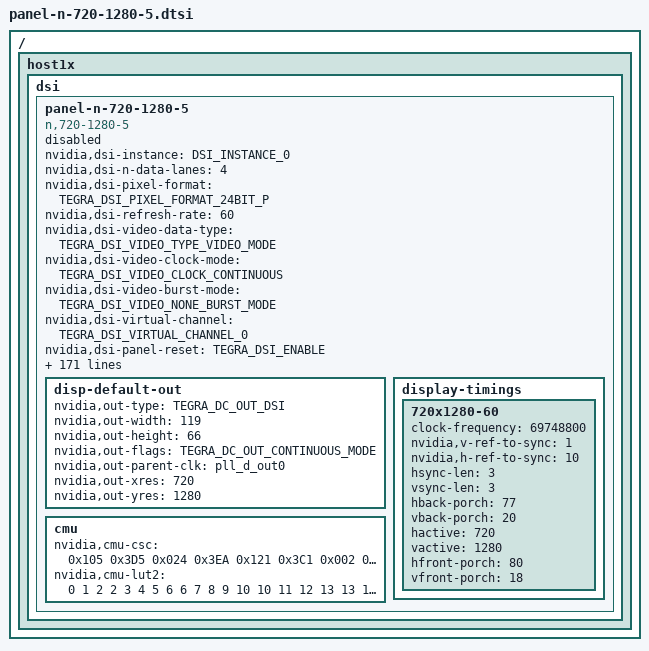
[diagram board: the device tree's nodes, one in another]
/*
 * arch/arm/boot/dts/panel-n-720-1280-5.dtsi
 *
 * Copyright (c) 2014, NVIDIA CORPORATION.  All rights reserved.
 *
 * This program is free software; you can redistribute it and/or modify
 * it under the terms of the GNU General Public License as published by
 * the Free Software Foundation; either version 2 of the License, or
 * (at your option) any later version.
 *
 * This program is distributed in the hope that it will be useful, but WITHOUT
 * ANY WARRANTY; without even the implied warranty of MERCHANTABILITY or
 * FITNESS FOR A PARTICULAR PURPOSE.  See the GNU General Public License for
 * more details.
 *
 * You should have received a copy of the GNU General Public License along
 * with this program; if not, write to the Free Software Foundation, Inc.,
 * 51 Franklin Street, Fifth Floor, Boston, MA  02110-1301, USA.
 */
#include <dt-bindings/display/tegra-dc.h>
#include <dt-bindings/display/tegra-panel.h>

/ {
	host1x {
		dsi {
			panel-n-720-1280-5 {
				status = "disabled";
				compatible = "n,720-1280-5", "none,panel-generic";

				nvidia,dsi-instance = <DSI_INSTANCE_0>;
				nvidia,dsi-n-data-lanes = <4>;
				nvidia,dsi-pixel-format = <TEGRA_DSI_PIXEL_FORMAT_24BIT_P>;
				nvidia,dsi-refresh-rate = <60>;
				nvidia,dsi-video-data-type = <TEGRA_DSI_VIDEO_TYPE_VIDEO_MODE>;
				nvidia,dsi-video-clock-mode = <TEGRA_DSI_VIDEO_CLOCK_CONTINUOUS>;
				nvidia,dsi-video-burst-mode = <TEGRA_DSI_VIDEO_NONE_BURST_MODE>;
				nvidia,dsi-virtual-channel = <TEGRA_DSI_VIRTUAL_CHANNEL_0>;
				nvidia,dsi-panel-reset = <TEGRA_DSI_ENABLE>;
				nvidia,dsi-power-saving-suspend = <TEGRA_DSI_ENABLE>;

				/* Long Packet: <PACKETTYPE[u8] COMMANDID[u8] PAYLOADCOUNT[u16] ECC[u8] PAYLOAD[..] CHECKSUM[u16]> */
				/* Short Packet: <PACKETTYPE[u8] COMMANDID[u8] DATA0[u8] DATA1[u8] ECC[u8]> */
				/* For DSI packets each DT cell is interpreted as u8 not u32 */
				nvidia,dsi-init-cmd =
					<TEGRA_DSI_DELAY_MS 130>,
					<TEGRA_DSI_PACKET_CMD DSI_GENERIC_LONG_WRITE 0x06 0x00 0x00 0xF0 0x55 0xAA 0x52 0x08 0x00 0x00 0x00>,
					<TEGRA_DSI_PACKET_CMD DSI_GENERIC_LONG_WRITE 0x05 0x00 0x00 0xFF 0xAA 0x55 0xA5 0x80 0x00 0x00>,
					<TEGRA_DSI_PACKET_CMD DSI_GENERIC_LONG_WRITE 0x02 0x00 0x00 0x6F 0x13 0x00 0x00>,
					<TEGRA_DSI_PACKET_CMD DSI_GENERIC_LONG_WRITE 0x02 0x00 0x00 0xF7 0x00 0x00 0x00>,
					<TEGRA_DSI_PACKET_CMD DSI_GENERIC_LONG_WRITE 0x02 0x00 0x00 0x6F 0x01 0x00 0x00>, /* ccmon */
					<TEGRA_DSI_PACKET_CMD DSI_GENERIC_LONG_WRITE 0x02 0x00 0x00 0xB1 0x21 0x00 0x00>,
					<TEGRA_DSI_PACKET_CMD DSI_GENERIC_LONG_WRITE 0x02 0x00 0x00 0x6F 0x02 0x00 0x00>,
					<TEGRA_DSI_PACKET_CMD DSI_GENERIC_LONG_WRITE 0x02 0x00 0x00 0xB8 0x0C 0x00 0x00>,
					<TEGRA_DSI_PACKET_CMD DSI_GENERIC_LONG_WRITE 0x03 0x00 0x00 0xBB 0x11 0x11 0x00 0x00>,
					<TEGRA_DSI_PACKET_CMD DSI_GENERIC_LONG_WRITE 0x03 0x00 0x00 0xBC 0x00 0x00 0x00 0x00>,
					<TEGRA_DSI_PACKET_CMD DSI_GENERIC_LONG_WRITE 0x02 0x00 0x00 0xB6 0x0F 0x00 0x00>, /* Modify by HSD */
					<TEGRA_DSI_PACKET_CMD DSI_GENERIC_LONG_WRITE 0x02 0x00 0x00 0xC8 0x80 0x00 0x00>,
					<TEGRA_DSI_PACKET_CMD DSI_GENERIC_LONG_WRITE 0x06 0x00 0x00 0xF0 0x55 0xAA 0x52 0x08 0x01 0x00 0x00>,
					<TEGRA_DSI_PACKET_CMD DSI_GENERIC_LONG_WRITE 0x03 0x00 0x00 0xB0 0x09 0x09 0x00 0x00>,
					<TEGRA_DSI_PACKET_CMD DSI_GENERIC_LONG_WRITE 0x03 0x00 0x00 0xB1 0x09 0x09 0x00 0x00>,
					<TEGRA_DSI_PACKET_CMD DSI_GENERIC_LONG_WRITE 0x03 0x00 0x00 0xBC 0xA0 0x00 0x00 0x00>,
					<TEGRA_DSI_PACKET_CMD DSI_GENERIC_LONG_WRITE 0x03 0x00 0x00 0xBD 0xA0 0x00 0x00 0x00>,
					<TEGRA_DSI_PACKET_CMD DSI_GENERIC_LONG_WRITE 0x02 0x00 0x00 0xCA 0x00 0x00 0x00>,
					<TEGRA_DSI_PACKET_CMD DSI_GENERIC_LONG_WRITE 0x02 0x00 0x00 0xC0 0x04 0x00 0x00>,
					<TEGRA_DSI_PACKET_CMD DSI_GENERIC_LONG_WRITE 0x03 0x00 0x00 0xB5 0x03 0x03 0x00 0x00>,
					<TEGRA_DSI_PACKET_CMD DSI_GENERIC_LONG_WRITE 0x02 0x00 0x00 0xBE 0x60 0x00 0x00>,
					<TEGRA_DSI_PACKET_CMD DSI_GENERIC_LONG_WRITE 0x03 0x00 0x00 0xB3 0x28 0x28 0x00 0x00>,
					<TEGRA_DSI_PACKET_CMD DSI_GENERIC_LONG_WRITE 0x03 0x00 0x00 0xB4 0x0F 0x0F 0x00 0x00>,
					<TEGRA_DSI_PACKET_CMD DSI_GENERIC_LONG_WRITE 0x03 0x00 0x00 0xB9 0x35 0x35 0x00 0x00>,
					<TEGRA_DSI_PACKET_CMD DSI_GENERIC_LONG_WRITE 0x03 0x00 0x00 0xBA 0x14 0x14 0x00 0x00>,
					<TEGRA_DSI_PACKET_CMD DSI_GENERIC_LONG_WRITE 0x06 0x00 0x00 0xF0 0x55 0xAA 0x52 0x08 0x02 0x00 0x00>,
					<TEGRA_DSI_PACKET_CMD DSI_GENERIC_LONG_WRITE 0x02 0x00 0x00 0xEE 0x01 0x00 0x00>,
					<TEGRA_DSI_PACKET_CMD DSI_GENERIC_LONG_WRITE 0x11 0x00 0x00 0xB0 0x00 0x00 0x00 0x17 0x00 0x3C 0x00 0x58 0x00 0x6D 0x00 0x92 0x00 0xAA 0x00 0xE2 0x00 0x00>, /* New GMA code */
					<TEGRA_DSI_PACKET_CMD DSI_GENERIC_LONG_WRITE 0x11 0x00 0x00 0xB1 0x01 0x08 0x01 0x44 0x01 0x73 0x01 0xBD 0x01 0xFA 0x01 0xFD 0x02 0x38 0x02 0x74 0x00 0x00>,
					<TEGRA_DSI_PACKET_CMD DSI_GENERIC_LONG_WRITE 0x11 0x00 0x00 0xB2 0x02 0x9B 0x02 0xCB 0x02 0xEC 0x03 0x17 0x03 0x2F 0x03 0x4E 0x03 0x81 0x03 0xD6 0x00 0x00>,
					<TEGRA_DSI_PACKET_CMD DSI_GENERIC_LONG_WRITE 0x05 0x00 0x00 0xB3 0x03 0xFB 0x03 0xFF 0x00 0x00>,
					<TEGRA_DSI_PACKET_CMD DSI_GENERIC_LONG_WRITE 0x06 0x00 0x00 0xF0 0x55 0xAA 0x52 0x08 0x06 0x00 0x00>,
					<TEGRA_DSI_PACKET_CMD DSI_GENERIC_LONG_WRITE 0x03 0x00 0x00 0xB0 0x2D 0x2E 0x00 0x00>,
					<TEGRA_DSI_PACKET_CMD DSI_GENERIC_LONG_WRITE 0x03 0x00 0x00 0xB1 0x29 0x2A 0x00 0x00>,
					<TEGRA_DSI_PACKET_CMD DSI_GENERIC_LONG_WRITE 0x03 0x00 0x00 0xB2 0x16 0x18 0x00 0x00>,
					<TEGRA_DSI_PACKET_CMD DSI_GENERIC_LONG_WRITE 0x03 0x00 0x00 0xB3 0x10 0x12 0x00 0x00>,
					<TEGRA_DSI_PACKET_CMD DSI_GENERIC_LONG_WRITE 0x03 0x00 0x00 0xB4 0x00 0x02 0x00 0x00>,
					<TEGRA_DSI_PACKET_CMD DSI_GENERIC_LONG_WRITE 0x03 0x00 0x00 0xB5 0x31 0x31 0x00 0x00>,
					<TEGRA_DSI_PACKET_CMD DSI_GENERIC_LONG_WRITE 0x03 0x00 0x00 0xB6 0x31 0x31 0x00 0x00>,
					<TEGRA_DSI_PACKET_CMD DSI_GENERIC_LONG_WRITE 0x03 0x00 0x00 0xB7 0x31 0x31 0x00 0x00>,
					<TEGRA_DSI_PACKET_CMD DSI_GENERIC_LONG_WRITE 0x03 0x00 0x00 0xB8 0x31 0x31 0x00 0x00>,
					<TEGRA_DSI_PACKET_CMD DSI_GENERIC_LONG_WRITE 0x03 0x00 0x00 0xB9 0x31 0x31 0x00 0x00>,
					<TEGRA_DSI_PACKET_CMD DSI_GENERIC_LONG_WRITE 0x03 0x00 0x00 0xBA 0x31 0x31 0x00 0x00>,
					<TEGRA_DSI_PACKET_CMD DSI_GENERIC_LONG_WRITE 0x03 0x00 0x00 0xBB 0x31 0x31 0x00 0x00>,
					<TEGRA_DSI_PACKET_CMD DSI_GENERIC_LONG_WRITE 0x03 0x00 0x00 0xBC 0x31 0x31 0x00 0x00>,
					<TEGRA_DSI_PACKET_CMD DSI_GENERIC_LONG_WRITE 0x03 0x00 0x00 0xBD 0x31 0x31 0x00 0x00>,
					<TEGRA_DSI_PACKET_CMD DSI_GENERIC_LONG_WRITE 0x03 0x00 0x00 0xBE 0x31 0x31 0x00 0x00>,
					<TEGRA_DSI_PACKET_CMD DSI_GENERIC_LONG_WRITE 0x03 0x00 0x00 0xBF 0x03 0x01 0x00 0x00>,
					<TEGRA_DSI_PACKET_CMD DSI_GENERIC_LONG_WRITE 0x03 0x00 0x00 0xC0 0x13 0x11 0x00 0x00>,
					<TEGRA_DSI_PACKET_CMD DSI_GENERIC_LONG_WRITE 0x03 0x00 0x00 0xC1 0x19 0x17 0x00 0x00>,
					<TEGRA_DSI_PACKET_CMD DSI_GENERIC_LONG_WRITE 0x03 0x00 0x00 0xC2 0x2A 0x29 0x00 0x00>,
					<TEGRA_DSI_PACKET_CMD DSI_GENERIC_LONG_WRITE 0x03 0x00 0x00 0xC3 0x2E 0x2D 0x00 0x00>,
					<TEGRA_DSI_PACKET_CMD DSI_GENERIC_LONG_WRITE 0x03 0x00 0x00 0xE5 0x31 0x31 0x00 0x00>,
					<TEGRA_DSI_PACKET_CMD DSI_GENERIC_LONG_WRITE 0x03 0x00 0x00 0xC4 0x2E 0x2D 0x00 0x00>,
					<TEGRA_DSI_PACKET_CMD DSI_GENERIC_LONG_WRITE 0x03 0x00 0x00 0xC5 0x29 0x2A 0x00 0x00>,
					<TEGRA_DSI_PACKET_CMD DSI_GENERIC_LONG_WRITE 0x03 0x00 0x00 0xC6 0x13 0x11 0x00 0x00>,
					<TEGRA_DSI_PACKET_CMD DSI_GENERIC_LONG_WRITE 0x03 0x00 0x00 0xC7 0x19 0x17 0x00 0x00>,
					<TEGRA_DSI_PACKET_CMD DSI_GENERIC_LONG_WRITE 0x03 0x00 0x00 0xC8 0x03 0x01 0x00 0x00>,
					<TEGRA_DSI_PACKET_CMD DSI_GENERIC_LONG_WRITE 0x03 0x00 0x00 0xC9 0x31 0x31 0x00 0x00>,
					<TEGRA_DSI_PACKET_CMD DSI_GENERIC_LONG_WRITE 0x03 0x00 0x00 0xCA 0x31 0x31 0x00 0x00>,
					<TEGRA_DSI_PACKET_CMD DSI_GENERIC_LONG_WRITE 0x03 0x00 0x00 0xCB 0x31 0x31 0x00 0x00>,
					<TEGRA_DSI_PACKET_CMD DSI_GENERIC_LONG_WRITE 0x03 0x00 0x00 0xCC 0x31 0x31 0x00 0x00>,
					<TEGRA_DSI_PACKET_CMD DSI_GENERIC_LONG_WRITE 0x03 0x00 0x00 0xCD 0x31 0x31 0x00 0x00>,
					<TEGRA_DSI_PACKET_CMD DSI_GENERIC_LONG_WRITE 0x03 0x00 0x00 0xCE 0x31 0x31 0x00 0x00>,
					<TEGRA_DSI_PACKET_CMD DSI_GENERIC_LONG_WRITE 0x03 0x00 0x00 0xCF 0x31 0x31 0x00 0x00>,
					<TEGRA_DSI_PACKET_CMD DSI_GENERIC_LONG_WRITE 0x03 0x00 0x00 0xD0 0x31 0x31 0x00 0x00>,
					<TEGRA_DSI_PACKET_CMD DSI_GENERIC_LONG_WRITE 0x03 0x00 0x00 0xD1 0x31 0x31 0x00 0x00>,
					<TEGRA_DSI_PACKET_CMD DSI_GENERIC_LONG_WRITE 0x03 0x00 0x00 0xD2 0x31 0x31 0x00 0x00>,
					<TEGRA_DSI_PACKET_CMD DSI_GENERIC_LONG_WRITE 0x03 0x00 0x00 0xD3 0x00 0x02 0x00 0x00>,
					<TEGRA_DSI_PACKET_CMD DSI_GENERIC_LONG_WRITE 0x03 0x00 0x00 0xD4 0x16 0x18 0x00 0x00>,
					<TEGRA_DSI_PACKET_CMD DSI_GENERIC_LONG_WRITE 0x03 0x00 0x00 0xD5 0x10 0x12 0x00 0x00>,
					<TEGRA_DSI_PACKET_CMD DSI_GENERIC_LONG_WRITE 0x03 0x00 0x00 0xD6 0x2A 0x29 0x00 0x00>,
					<TEGRA_DSI_PACKET_CMD DSI_GENERIC_LONG_WRITE 0x03 0x00 0x00 0xD7 0x2D 0x2E 0x00 0x00>,
					<TEGRA_DSI_PACKET_CMD DSI_GENERIC_LONG_WRITE 0x03 0x00 0x00 0xE6 0x31 0x31 0x00 0x00>,
					<TEGRA_DSI_PACKET_CMD DSI_GENERIC_LONG_WRITE 0x06 0x00 0x00 0xD8 0x00 0x00 0x00 0x00 0x00 0x00 0x00>,
					<TEGRA_DSI_PACKET_CMD DSI_GENERIC_LONG_WRITE 0x06 0x00 0x00 0xD9 0x00 0x00 0x00 0x00 0x00 0x00 0x00>,
					<TEGRA_DSI_PACKET_CMD DSI_GENERIC_LONG_WRITE 0x02 0x00 0x00 0xE7 0x00 0x00 0x00>,
					<TEGRA_DSI_PACKET_CMD DSI_GENERIC_LONG_WRITE 0x06 0x00 0x00 0xF0 0x55 0xAA 0x52 0x08 0x05 0x00 0x00>, /*PAGE5 : dof_opt_en, clr_opt_en*/
					<TEGRA_DSI_PACKET_CMD DSI_GENERIC_LONG_WRITE 0x02 0x00 0x00 0xED 0x30 0x00 0x00>,
					<TEGRA_DSI_PACKET_CMD DSI_GENERIC_LONG_WRITE 0x06 0x00 0x00 0xF0 0x55 0xAA 0x52 0x08 0x03 0x00 0x00>,
					<TEGRA_DSI_PACKET_CMD DSI_GENERIC_LONG_WRITE 0x03 0x00 0x00 0xB1 0x20 0x00 0x00 0x00>,
					<TEGRA_DSI_PACKET_CMD DSI_GENERIC_LONG_WRITE 0x03 0x00 0x00 0xB0 0x20 0x00 0x00 0x00>,
					<TEGRA_DSI_PACKET_CMD DSI_GENERIC_LONG_WRITE 0x06 0x00 0x00 0xF0 0x55 0xAA 0x52 0x08 0x05 0x00 0x00>,
					<TEGRA_DSI_PACKET_CMD DSI_GENERIC_LONG_WRITE 0x02 0x00 0x00 0xE5 0x00 0x00 0x00>,
					<TEGRA_DSI_PACKET_CMD DSI_GENERIC_LONG_WRITE 0x06 0x00 0x00 0xF0 0x55 0xAA 0x52 0x08 0x05 0x00 0x00>, /*PAGE5 : Initial & On/Off*/
					<TEGRA_DSI_PACKET_CMD DSI_GENERIC_LONG_WRITE 0x03 0x00 0x00 0xB0 0x17 0x06 0x00 0x00>,
					<TEGRA_DSI_PACKET_CMD DSI_GENERIC_LONG_WRITE 0x02 0x00 0x00 0xB8 0x00 0x00 0x00>,
					<TEGRA_DSI_PACKET_CMD DSI_GENERIC_LONG_WRITE 0x06 0x00 0x00 0xBD 0x03 0x03 0x00 0x03 0x03 0x00 0x00>,
					<TEGRA_DSI_PACKET_CMD DSI_GENERIC_LONG_WRITE 0x03 0x00 0x00 0xB1 0x17 0x06 0x00 0x00>,
					<TEGRA_DSI_PACKET_CMD DSI_GENERIC_LONG_WRITE 0x03 0x00 0x00 0xB9 0x00 0x03 0x00 0x00>,
					<TEGRA_DSI_PACKET_CMD DSI_GENERIC_LONG_WRITE 0x03 0x00 0x00 0xB2 0x17 0x06 0x00 0x00>,
					<TEGRA_DSI_PACKET_CMD DSI_GENERIC_LONG_WRITE 0x03 0x00 0x00 0xBA 0x00 0x00 0x00 0x00>,
					<TEGRA_DSI_PACKET_CMD DSI_GENERIC_LONG_WRITE 0x03 0x00 0x00 0xB3 0x17 0x06 0x00 0x00>,
					<TEGRA_DSI_PACKET_CMD DSI_GENERIC_LONG_WRITE 0x03 0x00 0x00 0xBB 0x02 0x03 0x00 0x00>,
					<TEGRA_DSI_PACKET_CMD DSI_GENERIC_LONG_WRITE 0x03 0x00 0x00 0xB4 0x17 0x06 0x00 0x00>,
					<TEGRA_DSI_PACKET_CMD DSI_GENERIC_LONG_WRITE 0x03 0x00 0x00 0xB5 0x17 0x06 0x00 0x00>,
					<TEGRA_DSI_PACKET_CMD DSI_GENERIC_LONG_WRITE 0x03 0x00 0x00 0xB6 0x17 0x06 0x00 0x00>,
					<TEGRA_DSI_PACKET_CMD DSI_GENERIC_LONG_WRITE 0x03 0x00 0x00 0xB7 0x17 0x06 0x00 0x00>,
					<TEGRA_DSI_PACKET_CMD DSI_GENERIC_LONG_WRITE 0x03 0x00 0x00 0xBC 0x02 0x03 0x00 0x00>,
					<TEGRA_DSI_PACKET_CMD DSI_GENERIC_LONG_WRITE 0x02 0x00 0x00 0xE5 0x06 0x00 0x00>,
					<TEGRA_DSI_PACKET_CMD DSI_GENERIC_LONG_WRITE 0x02 0x00 0x00 0xE6 0x06 0x00 0x00>,
					<TEGRA_DSI_PACKET_CMD DSI_GENERIC_LONG_WRITE 0x02 0x00 0x00 0xE7 0x00 0x00 0x00>,
					<TEGRA_DSI_PACKET_CMD DSI_GENERIC_LONG_WRITE 0x02 0x00 0x00 0xE8 0x06 0x00 0x00>,
					<TEGRA_DSI_PACKET_CMD DSI_GENERIC_LONG_WRITE 0x02 0x00 0x00 0xE9 0x06 0x00 0x00>,
					<TEGRA_DSI_PACKET_CMD DSI_GENERIC_LONG_WRITE 0x02 0x00 0x00 0xEA 0x06 0x00 0x00>,
					<TEGRA_DSI_PACKET_CMD DSI_GENERIC_LONG_WRITE 0x02 0x00 0x00 0xEB 0x00 0x00 0x00>,
					<TEGRA_DSI_PACKET_CMD DSI_GENERIC_LONG_WRITE 0x02 0x00 0x00 0xEC 0x00 0x00 0x00>,
					<TEGRA_DSI_PACKET_CMD DSI_GENERIC_LONG_WRITE 0x06 0x00 0x00 0xF0 0x55 0xAA 0x52 0x08 0x05 0x00 0x00>, /*STV Settings*/
					<TEGRA_DSI_PACKET_CMD DSI_GENERIC_LONG_WRITE 0x02 0x00 0x00 0xC0 0x0B 0x00 0x00>,
					<TEGRA_DSI_PACKET_CMD DSI_GENERIC_LONG_WRITE 0x02 0x00 0x00 0xC1 0x09 0x00 0x00>,
					<TEGRA_DSI_PACKET_CMD DSI_GENERIC_LONG_WRITE 0x02 0x00 0x00 0xC2 0xA6 0x00 0x00>,
					<TEGRA_DSI_PACKET_CMD DSI_GENERIC_LONG_WRITE 0x02 0x00 0x00 0xC3 0x05 0x00 0x00>,
					<TEGRA_DSI_PACKET_CMD DSI_GENERIC_LONG_WRITE 0x06 0x00 0x00 0xF0 0x55 0xAA 0x52 0x08 0x03 0x00 0x00>,
					<TEGRA_DSI_PACKET_CMD DSI_GENERIC_LONG_WRITE 0x06 0x00 0x00 0xB2 0x05 0x00 0x4B 0x00 0x00 0x00 0x00>,
					<TEGRA_DSI_PACKET_CMD DSI_GENERIC_LONG_WRITE 0x06 0x00 0x00 0xB3 0x05 0x00 0x4B 0x00 0x00 0x00 0x00>,
					<TEGRA_DSI_PACKET_CMD DSI_GENERIC_LONG_WRITE 0x06 0x00 0x00 0xB4 0x05 0x00 0x17 0x00 0x00 0x00 0x00>,
					<TEGRA_DSI_PACKET_CMD DSI_GENERIC_LONG_WRITE 0x06 0x00 0x00 0xB5 0x05 0x00 0x17 0x00 0x00 0x00 0x00>,
					<TEGRA_DSI_PACKET_CMD DSI_GENERIC_LONG_WRITE 0x06 0x00 0x00 0xF0 0x55 0xAA 0x52 0x08 0x05 0x00 0x00>, /*RST Settings*/
					<TEGRA_DSI_PACKET_CMD DSI_GENERIC_LONG_WRITE 0x02 0x00 0x00 0xC4 0x00 0x00 0x00>,
					<TEGRA_DSI_PACKET_CMD DSI_GENERIC_LONG_WRITE 0x02 0x00 0x00 0xC5 0x02 0x00 0x00>,
					<TEGRA_DSI_PACKET_CMD DSI_GENERIC_LONG_WRITE 0x02 0x00 0x00 0xC6 0x22 0x00 0x00>,
					<TEGRA_DSI_PACKET_CMD DSI_GENERIC_LONG_WRITE 0x02 0x00 0x00 0xC7 0x03 0x00 0x00>,
					<TEGRA_DSI_PACKET_CMD DSI_GENERIC_LONG_WRITE 0x06 0x00 0x00 0xF0 0x55 0xAA 0x52 0x08 0x03 0x00 0x00>,
					<TEGRA_DSI_PACKET_CMD DSI_GENERIC_LONG_WRITE 0x06 0x00 0x00 0xB6 0x02 0x00 0x19 0x00 0x00 0x00 0x00>,
					<TEGRA_DSI_PACKET_CMD DSI_GENERIC_LONG_WRITE 0x06 0x00 0x00 0xB7 0x02 0x00 0x19 0x00 0x00 0x00 0x00>,
					<TEGRA_DSI_PACKET_CMD DSI_GENERIC_LONG_WRITE 0x06 0x00 0x00 0xB8 0x02 0x00 0x19 0x00 0x00 0x00 0x00>,
					<TEGRA_DSI_PACKET_CMD DSI_GENERIC_LONG_WRITE 0x06 0x00 0x00 0xB9 0x02 0x00 0x19 0x00 0x00 0x00 0x00>,
					<TEGRA_DSI_PACKET_CMD DSI_GENERIC_LONG_WRITE 0x06 0x00 0x00 0xF0 0x55 0xAA 0x52 0x08 0x05 0x00 0x00>, /*CLK Settings*/
					<TEGRA_DSI_PACKET_CMD DSI_GENERIC_LONG_WRITE 0x03 0x00 0x00 0xC8 0x07 0x20 0x00 0x00>,
					<TEGRA_DSI_PACKET_CMD DSI_GENERIC_LONG_WRITE 0x03 0x00 0x00 0xC9 0x03 0x20 0x00 0x00>,
					<TEGRA_DSI_PACKET_CMD DSI_GENERIC_LONG_WRITE 0x03 0x00 0x00 0xCA 0x01 0x60 0x00 0x00>,
					<TEGRA_DSI_PACKET_CMD DSI_GENERIC_LONG_WRITE 0x03 0x00 0x00 0xCB 0x01 0x60 0x00 0x00>,
					<TEGRA_DSI_PACKET_CMD DSI_GENERIC_LONG_WRITE 0x06 0x00 0x00 0xF0 0x55 0xAA 0x52 0x08 0x03 0x00 0x00>, /*Modify by HSD*/
					<TEGRA_DSI_PACKET_CMD DSI_GENERIC_LONG_WRITE 0x06 0x00 0x00 0xBA 0x53 0x00 0x4B 0x00 0x00 0x00 0x00>,
					<TEGRA_DSI_PACKET_CMD DSI_GENERIC_LONG_WRITE 0x06 0x00 0x00 0xBB 0x53 0x00 0x4B 0x00 0x00 0x00 0x00>,
					<TEGRA_DSI_PACKET_CMD DSI_GENERIC_LONG_WRITE 0x06 0x00 0x00 0xBC 0x53 0x00 0x1A 0x00 0x00 0x00 0x00>,
					<TEGRA_DSI_PACKET_CMD DSI_GENERIC_LONG_WRITE 0x06 0x00 0x00 0xBD 0x53 0x00 0x1A 0x00 0x00 0x00 0x00>,
					<TEGRA_DSI_PACKET_CMD DSI_GENERIC_LONG_WRITE 0x06 0x00 0x00 0xF0 0x55 0xAA 0x52 0x08 0x05 0x00 0x00>, /*CLK Porch Settings*/
					<TEGRA_DSI_PACKET_CMD DSI_GENERIC_LONG_WRITE 0x06 0x00 0x00 0xD1 0x00 0x05 0x01 0x07 0x10 0x00 0x00>,
					<TEGRA_DSI_PACKET_CMD DSI_GENERIC_LONG_WRITE 0x06 0x00 0x00 0xD2 0x10 0x05 0x05 0x03 0x10 0x00 0x00>,
					<TEGRA_DSI_PACKET_CMD DSI_GENERIC_LONG_WRITE 0x06 0x00 0x00 0xD3 0x20 0x00 0x43 0x07 0x10 0x00 0x00>,
					<TEGRA_DSI_PACKET_CMD DSI_GENERIC_LONG_WRITE 0x06 0x00 0x00 0xD4 0x30 0x00 0x43 0x07 0x10 0x00 0x00>,
					<TEGRA_DSI_PACKET_CMD DSI_GENERIC_LONG_WRITE 0x06 0x00 0x00 0xF0 0x55 0xAA 0x52 0x08 0x05 0x00 0x00>, /*CLK Mask Settings*/
					<TEGRA_DSI_PACKET_CMD DSI_GENERIC_LONG_WRITE 0x08 0x00 0x00 0xD0 0x00 0x00 0x00 0x00 0x00 0x00 0x00 0x00 0x00>,
					<TEGRA_DSI_PACKET_CMD DSI_GENERIC_LONG_WRITE 0x0C 0x00 0x00 0xD5 0x00 0x00 0x00 0x00 0x00 0x00 0x00 0x00 0x00 0x00 0x00 0x00 0x00>,
					<TEGRA_DSI_PACKET_CMD DSI_GENERIC_LONG_WRITE 0x0C 0x00 0x00 0xD6 0x00 0x00 0x00 0x00 0x00 0x00 0x00 0x00 0x00 0x00 0x00 0x00 0x00>,
					<TEGRA_DSI_PACKET_CMD DSI_GENERIC_LONG_WRITE 0x0C 0x00 0x00 0xD7 0x00 0x00 0x00 0x00 0x00 0x00 0x00 0x00 0x00 0x00 0x00 0x00 0x00>,
					<TEGRA_DSI_PACKET_CMD DSI_GENERIC_LONG_WRITE 0x06 0x00 0x00 0xD8 0x00 0x00 0x00 0x00 0x00 0x00 0x00>,
					<TEGRA_DSI_PACKET_CMD DSI_GENERIC_LONG_WRITE 0x06 0x00 0x00 0xF0 0x55 0xAA 0x52 0x08 0x05 0x00 0x00>, /*VAC Settings*/
					<TEGRA_DSI_PACKET_CMD DSI_GENERIC_LONG_WRITE 0x04 0x00 0x00 0xCC 0x00 0x00 0x01 0x00 0x00>,
					<TEGRA_DSI_PACKET_CMD DSI_GENERIC_LONG_WRITE 0x04 0x00 0x00 0xCD 0x00 0x00 0x01 0x00 0x00>,
					<TEGRA_DSI_PACKET_CMD DSI_GENERIC_LONG_WRITE 0x04 0x00 0x00 0xCE 0x00 0x00 0x02 0x00 0x00>,
					<TEGRA_DSI_PACKET_CMD DSI_GENERIC_LONG_WRITE 0x04 0x00 0x00 0xCF 0x00 0x00 0x02 0x00 0x00>,
					<TEGRA_DSI_PACKET_CMD DSI_GENERIC_LONG_WRITE 0x06 0x00 0x00 0xF0 0x55 0xAA 0x52 0x08 0x03 0x00 0x00>,
					<TEGRA_DSI_PACKET_CMD DSI_GENERIC_LONG_WRITE 0x05 0x00 0x00 0xC0 0x00 0x34 0x00 0x00 0x00 0x00>,
					<TEGRA_DSI_PACKET_CMD DSI_GENERIC_LONG_WRITE 0x05 0x00 0x00 0xC1 0x00 0x00 0x34 0x00 0x00 0x00>,
					<TEGRA_DSI_PACKET_CMD DSI_GENERIC_LONG_WRITE 0x05 0x00 0x00 0xC2 0x00 0x00 0x34 0x00 0x00 0x00>,
					<TEGRA_DSI_PACKET_CMD DSI_GENERIC_LONG_WRITE 0x05 0x00 0x00 0xC3 0x00 0x00 0x34 0x00 0x00 0x00>,
					<TEGRA_DSI_PACKET_CMD DSI_GENERIC_LONG_WRITE 0x06 0x00 0x00 0xF0 0x55 0xAA 0x52 0x08 0x03 0x00 0x00>, /*VDC Settings*/
					<TEGRA_DSI_PACKET_CMD DSI_GENERIC_LONG_WRITE 0x02 0x00 0x00 0xC4 0x60 0x00 0x00>,
					<TEGRA_DSI_PACKET_CMD DSI_GENERIC_LONG_WRITE 0x02 0x00 0x00 0xC5 0xC0 0x00 0x00>,
					<TEGRA_DSI_PACKET_CMD DSI_GENERIC_LONG_WRITE 0x02 0x00 0x00 0xC6 0x00 0x00 0x00>,
					<TEGRA_DSI_PACKET_CMD DSI_GENERIC_LONG_WRITE 0x02 0x00 0x00 0xC7 0x00 0x00 0x00>,
					<TEGRA_DSI_PACKET_CMD DSI_DCS_WRITE_0_PARAM DSI_DCS_EXIT_SLEEP_MODE 0x0 0x0>,
					<TEGRA_DSI_DELAY_MS 130>,
					<TEGRA_DSI_PACKET_CMD DSI_DCS_WRITE_0_PARAM DSI_DCS_SET_DISPLAY_ON 0x0 0x0>,
					<TEGRA_DSI_DELAY_MS 20>;
				nvidia,dsi-n-init-cmd = <168>;

				/* Kept for reference: display a test pattern from the controller chip for the display */
				/*
					<TEGRA_DSI_PACKET_CMD DSI_GENERIC_LONG_WRITE 0x06 0x00 0x00 0xF0 0x55 0xAA 0x52 0x08 0x00 0x00 0x00>,
					<TEGRA_DSI_PACKET_CMD DSI_GENERIC_LONG_WRITE 0x05 0x00 0x00 0xEF 0x00 0xFF 0xFF 0xFF 0x00 0x00>,
					<TEGRA_DSI_PACKET_CMD DSI_GENERIC_LONG_WRITE 0x05 0x00 0x00 0xEE 0x87 0x78 0x02 0x40 0x00 0x00>;
				nvidia,dsi-n-init-cmd = <171>;
				*/

				disp-default-out {
					nvidia,out-type = <TEGRA_DC_OUT_DSI>;
					nvidia,out-width = <119>;
					nvidia,out-height = <66>;
					nvidia,out-flags = <TEGRA_DC_OUT_CONTINUOUS_MODE>;
					nvidia,out-parent-clk = "pll_d_out0";
					nvidia,out-xres = <720>;
					nvidia,out-yres = <1280>;
				};
				display-timings {
					720x1280-60 {
						/* (720+80+77+3) x (1280+18+20+3) x 60 */
						clock-frequency = <69748800>;
						nvidia,v-ref-to-sync = <1>;
						nvidia,h-ref-to-sync = <10>;
						hsync-len = <3>;
						vsync-len = <3>;
						hback-porch = <77>;
						vback-porch = <20>;
						hactive = <720>;
						vactive = <1280>;
						hfront-porch = <80>;
						vfront-porch = <18>;
					};
				};

				cmu {
					nvidia,cmu-csc = < 0x105 0x3D5 0x024
							   0x3EA 0x121 0x3C1
							   0x002 0x00A 0x0F4 >;
					nvidia,cmu-lut2 = < 0 1 2 2 3 4 5 6
							    6 7 8 9 10 10 11 12
							    13 13 14 15 15 16 16 17
							    18 18 19 19 20 20 21 21
							    22 22 23 23 23 24 24 25
							    25 25 26 26 27 27 27 28
							    28 29 29 29 30 30 30 31
							    31 31 32 32 32 33 33 33
							    34 34 34 34 35 35 35 36
							    36 36 37 37 37 37 38 38
							    38 38 39 39 39 40 40 40
							    40 41 41 41 41 42 42 42
							    42 43 43 43 43 43 44 44
							    44 44 45 45 45 45 46 46
							    46 46 46 47 47 47 47 48
							    48 48 48 48 49 49 49 49
							    49 50 50 50 50 50 51 51
							    51 51 51 52 52 52 52 52
							    53 53 53 53 53 54 54 54
							    54 54 55 55 55 55 55 55
							    56 56 56 56 56 57 57 57
							    57 57 57 58 58 58 58 58
							    58 59 59 59 59 59 59 60
							    60 60 60 60 60 61 61 61
							    61 61 61 62 62 62 62 62
							    62 63 63 63 63 63 63 64
							    64 64 64 64 64 64 65 65
							    65 65 65 65 66 66 66 66
							    66 66 66 67 67 67 67 67
							    67 67 68 68 68 68 68 68
							    68 69 69 69 69 69 69 69
							    70 70 70 70 70 70 70 71
							    71 71 71 71 71 71 72 72
							    72 72 72 72 72 72 73 73
							    73 73 73 73 73 74 74 74
							    74 74 74 74 74 75 75 75
							    75 75 75 75 75 76 76 76
							    76 76 76 76 77 77 77 77
							    77 77 77 77 78 78 78 78
							    78 78 78 78 78 79 79 79
							    79 79 79 79 79 80 80 80
							    80 80 80 80 80 81 81 81
							    81 81 81 81 81 81 82 82
							    82 82 82 82 82 82 83 83
							    83 83 83 83 83 83 83 84
							    84 84 84 84 84 84 84 84
							    85 85 85 85 85 85 85 85
							    85 86 86 86 86 86 86 86
							    86 86 87 87 87 87 87 87
							    87 87 87 88 88 88 88 88
							    88 88 88 88 88 89 89 89
							    89 89 89 89 89 89 90 90
							    90 90 90 90 90 90 90 90
							    91 91 91 91 91 91 91 91
							    91 91 92 92 92 92 92 92
							    92 92 92 92 93 93 93 93
							    93 93 93 93 93 93 94 94
							    94 94 94 94 94 94 94 94
							    95 95 95 95 95 95 95 95
							    95 95 96 96 96 96 96 96
							    96 96 96 96 96 97 97 97
							    97 97 97 97 97 97 97 98
							    98 98 98 98 98 98 98 98
							    98 98 99 99 99 99 99 99
							    99 100 101 101 102 103 103 104
							    105 105 106 107 107 108 109 109
							    110 111 111 112 113 113 114 115
							    115 116 116 117 118 118 119 119
							    120 120 121 122 122 123 123 124
							    124 125 126 126 127 127 128 128
							    129 129 130 130 131 131 132 132
							    133 133 134 134 135 135 136 136
							    137 137 138 138 139 139 140 140
							    141 141 142 142 143 143 144 144
							    145 145 145 146 146 147 147 148
							    148 149 149 150 150 150 151 151
							    152 152 153 153 153 154 154 155
							    155 156 156 156 157 157 158 158
							    158 159 159 160 160 160 161 161
							    162 162 162 163 163 164 164 164
							    165 165 166 166 166 167 167 167
							    168 168 169 169 169 170 170 170
							    171 171 172 172 172 173 173 173
							    174 174 174 175 175 176 176 176
							    177 177 177 178 178 178 179 179
							    179 180 180 180 181 181 182 182
							    182 183 183 183 184 184 184 185
							    185 185 186 186 186 187 187 187
							    188 188 188 189 189 189 189 190
							    190 190 191 191 191 192 192 192
							    193 193 193 194 194 194 195 195
							    195 196 196 196 196 197 197 197
							    198 198 198 199 199 199 200 200
							    200 200 201 201 201 202 202 202
							    202 203 203 203 204 204 204 205
							    205 205 205 206 206 206 207 207
							    207 207 208 208 208 209 209 209
							    209 210 210 210 211 211 211 211
							    212 212 212 213 213 213 213 214
							    214 214 214 215 215 215 216 216
							    216 216 217 217 217 217 218 218
							    218 219 219 219 219 220 220 220
							    220 221 221 221 221 222 222 222
							    223 223 223 223 224 224 224 224
							    225 225 225 225 226 226 226 226
							    227 227 227 227 228 228 228 228
							    229 229 229 229 230 230 230 230
							    231 231 231 231 232 232 232 232
							    233 233 233 233 234 234 234 234
							    235 235 235 235 236 236 236 236
							    237 237 237 237 238 238 238 238
							    239 239 239 239 240 240 240 240
							    240 241 241 241 241 242 242 242
							    242 243 243 243 243 244 244 244
							    244 244 245 245 245 245 246 246
							    246 246 247 247 247 247 247 248
							    248 248 248 249 249 249 249 249
							    250 250 250 250 251 251 251 251
							    251 252 252 252 252 253 253 253
							    253 253 254 254 254 254 255 255 >;
				}; /* end cmu */
			};
		};
	};
};
